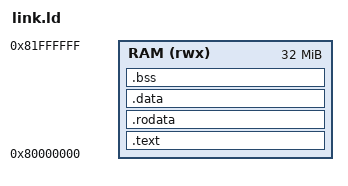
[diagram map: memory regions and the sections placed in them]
/* QEMU 'virt': RAM at 0x80000000.  Generous stack: ML-DSA's portable code keeps large arrays on it. */
OUTPUT_ARCH(riscv)
ENTRY(_start)
MEMORY { RAM (rwx) : ORIGIN = 0x80000000, LENGTH = 32M }
SECTIONS {
  .text : { *(.text.init) *(.text .text.*) } > RAM
  .rodata : { *(.rodata .rodata.* .srodata .srodata.*) } > RAM
  .data : { *(.data .data.* .sdata .sdata.*) } > RAM
  .bss : { __bss_start = .; *(.bss .bss.* .sbss .sbss.* COMMON) . = ALIGN(4); __bss_end = .; } > RAM
  . = ALIGN(16);
  . += 0x200000;
  __stack_top = .;
}
